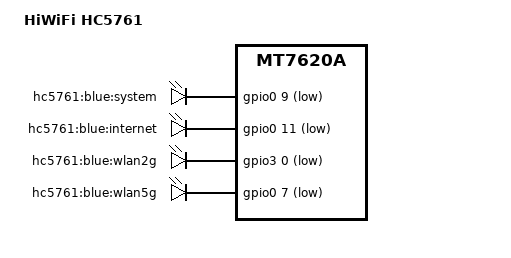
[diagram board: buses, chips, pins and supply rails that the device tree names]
/dts-v1/;

#include "HC5X61.dtsi"

/ {
	compatible = "hiwifi,hc5761", "hiwifi,hc5x61", "ralink,mt7620a-soc";
	model = "HiWiFi HC5761";

	aliases {
		led-status = &led_system;
	};

	gpio-leds {
		compatible = "gpio-leds";

		led_system: system {
			label = "hc5761:blue:system";
			gpios = <&gpio0 9 GPIO_ACTIVE_LOW>;
		};

		internet {
			label = "hc5761:blue:internet";
			gpios = <&gpio0 11 GPIO_ACTIVE_LOW>;
		};

		wlan2g {
			label = "hc5761:blue:wlan2g";
			gpios = <&gpio3 0 GPIO_ACTIVE_LOW>;
		};

		wlan5g {
			label = "hc5761:blue:wlan5g";
			gpios = <&gpio0 7 GPIO_ACTIVE_LOW>;
		};
	};
};
